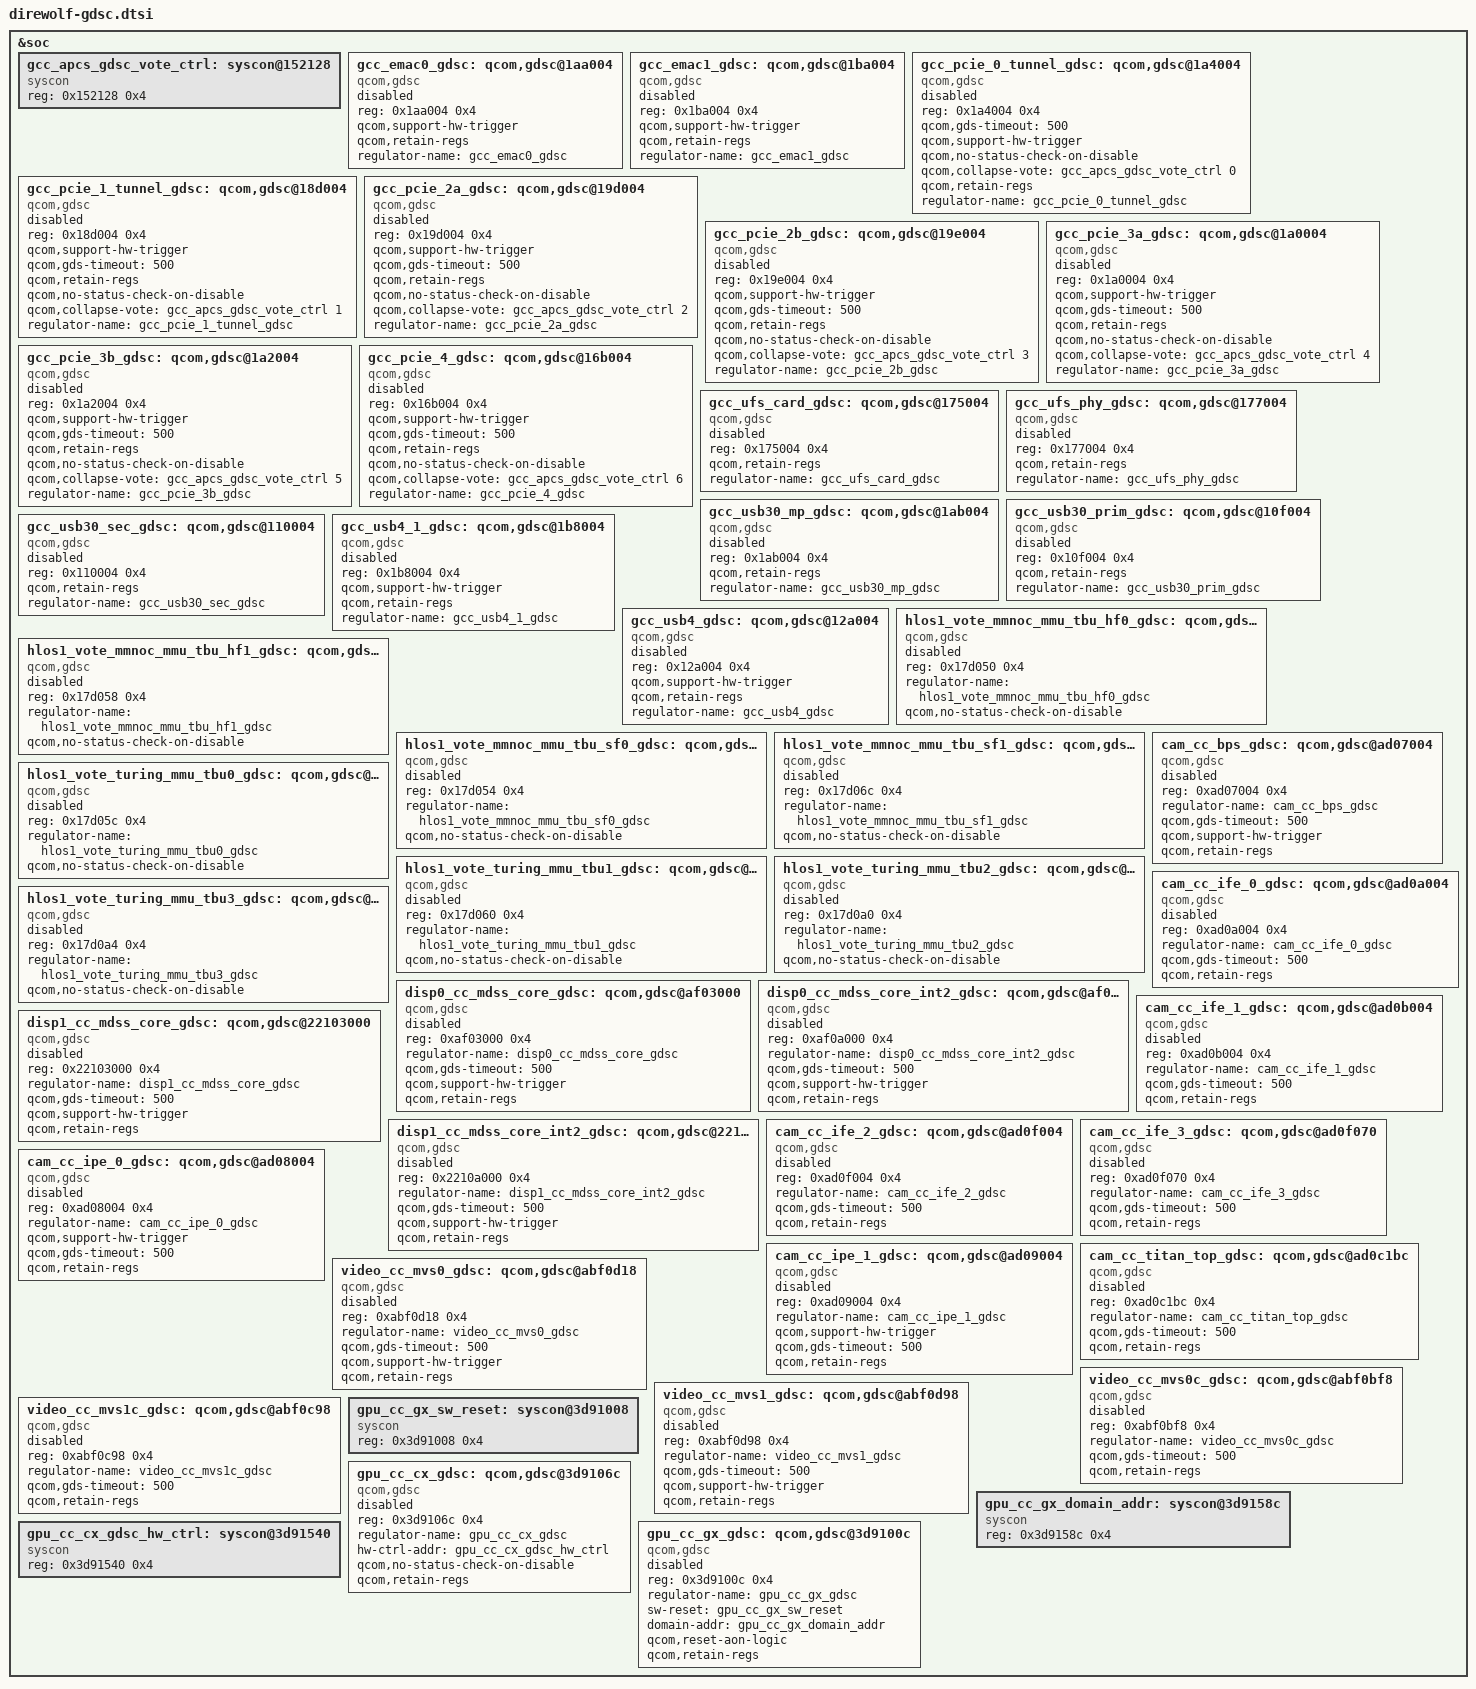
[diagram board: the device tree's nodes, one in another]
&soc {
	gcc_apcs_gdsc_vote_ctrl: syscon@152128 {
		compatible = "syscon";
		reg = <0x152128 0x4>;
	};

	/* GDSCs in GCC */
	gcc_emac0_gdsc: qcom,gdsc@1aa004 {
		compatible = "qcom,gdsc";
		reg = <0x1aa004 0x4>;
		qcom,support-hw-trigger;
		qcom,retain-regs;
		regulator-name = "gcc_emac0_gdsc";
		status = "disabled";
	};

	gcc_emac1_gdsc: qcom,gdsc@1ba004 {
		compatible = "qcom,gdsc";
		reg = <0x1ba004 0x4>;
		qcom,support-hw-trigger;
		qcom,retain-regs;
		regulator-name = "gcc_emac1_gdsc";
		status = "disabled";
	};

	gcc_pcie_0_tunnel_gdsc: qcom,gdsc@1a4004 {
		compatible = "qcom,gdsc";
		reg = <0x1a4004 0x4>;
		qcom,gds-timeout = <500>;
		qcom,support-hw-trigger;
		qcom,no-status-check-on-disable;
		qcom,collapse-vote = <&gcc_apcs_gdsc_vote_ctrl 0>;
		qcom,retain-regs;
		regulator-name = "gcc_pcie_0_tunnel_gdsc";
		status = "disabled";
	};

	gcc_pcie_1_tunnel_gdsc: qcom,gdsc@18d004 {
		compatible = "qcom,gdsc";
		reg = <0x18d004 0x4>;
		qcom,support-hw-trigger;
		qcom,gds-timeout = <500>;
		qcom,retain-regs;
		qcom,no-status-check-on-disable;
		qcom,collapse-vote = <&gcc_apcs_gdsc_vote_ctrl 1>;
		regulator-name = "gcc_pcie_1_tunnel_gdsc";
		status = "disabled";
	};

	gcc_pcie_2a_gdsc: qcom,gdsc@19d004 {
		compatible = "qcom,gdsc";
		reg = <0x19d004 0x4>;
		qcom,support-hw-trigger;
		qcom,gds-timeout = <500>;
		qcom,retain-regs;
		qcom,no-status-check-on-disable;
		qcom,collapse-vote = <&gcc_apcs_gdsc_vote_ctrl 2>;
		regulator-name = "gcc_pcie_2a_gdsc";
		status = "disabled";
	};

	gcc_pcie_2b_gdsc: qcom,gdsc@19e004 {
		compatible = "qcom,gdsc";
		reg = <0x19e004 0x4>;
		qcom,support-hw-trigger;
		qcom,gds-timeout = <500>;
		qcom,retain-regs;
		qcom,no-status-check-on-disable;
		qcom,collapse-vote = <&gcc_apcs_gdsc_vote_ctrl 3>;
		regulator-name = "gcc_pcie_2b_gdsc";
		status = "disabled";
	};

	gcc_pcie_3a_gdsc: qcom,gdsc@1a0004 {
		compatible = "qcom,gdsc";
		reg = <0x1a0004 0x4>;
		qcom,support-hw-trigger;
		qcom,gds-timeout = <500>;
		qcom,retain-regs;
		qcom,no-status-check-on-disable;
		qcom,collapse-vote = <&gcc_apcs_gdsc_vote_ctrl 4>;
		regulator-name = "gcc_pcie_3a_gdsc";
		status = "disabled";
	};

	gcc_pcie_3b_gdsc: qcom,gdsc@1a2004 {
		compatible = "qcom,gdsc";
		reg = <0x1a2004 0x4>;
		qcom,support-hw-trigger;
		qcom,gds-timeout = <500>;
		qcom,retain-regs;
		qcom,no-status-check-on-disable;
		qcom,collapse-vote = <&gcc_apcs_gdsc_vote_ctrl 5>;
		regulator-name = "gcc_pcie_3b_gdsc";
		status = "disabled";
	};

	gcc_pcie_4_gdsc: qcom,gdsc@16b004 {
		compatible = "qcom,gdsc";
		reg = <0x16b004 0x4>;
		qcom,support-hw-trigger;
		qcom,gds-timeout = <500>;
		qcom,retain-regs;
		qcom,no-status-check-on-disable;
		qcom,collapse-vote = <&gcc_apcs_gdsc_vote_ctrl 6>;
		regulator-name = "gcc_pcie_4_gdsc";
		status = "disabled";
	};

	gcc_ufs_card_gdsc: qcom,gdsc@175004 {
		compatible = "qcom,gdsc";
		reg = <0x175004 0x4>;
		qcom,retain-regs;
		regulator-name = "gcc_ufs_card_gdsc";
		status = "disabled";
	};

	gcc_ufs_phy_gdsc: qcom,gdsc@177004 {
		compatible = "qcom,gdsc";
		reg = <0x177004 0x4>;
		qcom,retain-regs;
		regulator-name = "gcc_ufs_phy_gdsc";
		status = "disabled";
	};

	gcc_usb30_mp_gdsc: qcom,gdsc@1ab004 {
		compatible = "qcom,gdsc";
		reg = <0x1ab004 0x4>;
		qcom,retain-regs;
		regulator-name = "gcc_usb30_mp_gdsc";
		status = "disabled";
	};

	gcc_usb30_prim_gdsc: qcom,gdsc@10f004 {
		compatible = "qcom,gdsc";
		reg = <0x10f004 0x4>;
		qcom,retain-regs;
		regulator-name = "gcc_usb30_prim_gdsc";
		status = "disabled";
	};

	gcc_usb30_sec_gdsc: qcom,gdsc@110004 {
		compatible = "qcom,gdsc";
		reg = <0x110004 0x4>;
		qcom,retain-regs;
		regulator-name = "gcc_usb30_sec_gdsc";
		status = "disabled";
	};

	gcc_usb4_1_gdsc: qcom,gdsc@1b8004 {
		compatible = "qcom,gdsc";
		reg = <0x1b8004 0x4>;
		qcom,support-hw-trigger;
		qcom,retain-regs;
		regulator-name = "gcc_usb4_1_gdsc";
		status = "disabled";
	};

	gcc_usb4_gdsc: qcom,gdsc@12a004 {
		compatible = "qcom,gdsc";
		reg = <0x12a004 0x4>;
		qcom,support-hw-trigger;
		qcom,retain-regs;
		regulator-name = "gcc_usb4_gdsc";
		status = "disabled";
	};

	hlos1_vote_mmnoc_mmu_tbu_hf0_gdsc: qcom,gdsc@17d050 {
		compatible = "qcom,gdsc";
		reg = <0x17d050 0x4>;
		regulator-name = "hlos1_vote_mmnoc_mmu_tbu_hf0_gdsc";
		qcom,no-status-check-on-disable;
		status = "disabled";
	};

	hlos1_vote_mmnoc_mmu_tbu_hf1_gdsc: qcom,gdsc@17d058 {
		compatible = "qcom,gdsc";
		reg = <0x17d058 0x4>;
		regulator-name = "hlos1_vote_mmnoc_mmu_tbu_hf1_gdsc";
		qcom,no-status-check-on-disable;
		status = "disabled";
	};

	hlos1_vote_mmnoc_mmu_tbu_sf0_gdsc: qcom,gdsc@17d054 {
		compatible = "qcom,gdsc";
		reg = <0x17d054 0x4>;
		regulator-name = "hlos1_vote_mmnoc_mmu_tbu_sf0_gdsc";
		qcom,no-status-check-on-disable;
		status = "disabled";
	};

	hlos1_vote_mmnoc_mmu_tbu_sf1_gdsc: qcom,gdsc@17d06c {
		compatible = "qcom,gdsc";
		reg = <0x17d06c 0x4>;
		regulator-name = "hlos1_vote_mmnoc_mmu_tbu_sf1_gdsc";
		qcom,no-status-check-on-disable;
		status = "disabled";
	};

	hlos1_vote_turing_mmu_tbu0_gdsc: qcom,gdsc@17d05c {
		compatible = "qcom,gdsc";
		reg = <0x17d05c 0x4>;
		regulator-name = "hlos1_vote_turing_mmu_tbu0_gdsc";
		qcom,no-status-check-on-disable;
		status = "disabled";
	};

	hlos1_vote_turing_mmu_tbu1_gdsc: qcom,gdsc@17d060 {
		compatible = "qcom,gdsc";
		reg = <0x17d060 0x4>;
		regulator-name = "hlos1_vote_turing_mmu_tbu1_gdsc";
		qcom,no-status-check-on-disable;
		status = "disabled";
	};

	hlos1_vote_turing_mmu_tbu2_gdsc: qcom,gdsc@17d0a0 {
		compatible = "qcom,gdsc";
		reg = <0x17d0a0 0x4>;
		regulator-name = "hlos1_vote_turing_mmu_tbu2_gdsc";
		qcom,no-status-check-on-disable;
		status = "disabled";
	};

	hlos1_vote_turing_mmu_tbu3_gdsc: qcom,gdsc@17d0a4 {
		compatible = "qcom,gdsc";
		reg = <0x17d0a4 0x4>;
		regulator-name = "hlos1_vote_turing_mmu_tbu3_gdsc";
		qcom,no-status-check-on-disable;
		status = "disabled";
	};

	/* DISP_CC_0 GDSCs */
	disp0_cc_mdss_core_gdsc: qcom,gdsc@af03000 {
		compatible = "qcom,gdsc";
		reg = <0xaf03000 0x4>;
		regulator-name = "disp0_cc_mdss_core_gdsc";
		qcom,gds-timeout = <500>;
		qcom,support-hw-trigger;
		qcom,retain-regs;
		status = "disabled";
	};

	disp0_cc_mdss_core_int2_gdsc: qcom,gdsc@af0a000 {
		compatible = "qcom,gdsc";
		reg = <0xaf0a000 0x4>;
		regulator-name = "disp0_cc_mdss_core_int2_gdsc";
		qcom,gds-timeout = <500>;
		qcom,support-hw-trigger;
		qcom,retain-regs;
		status = "disabled";
	};

	/* DISP_CC_1 GDSCs */
	disp1_cc_mdss_core_gdsc: qcom,gdsc@22103000 {
		compatible = "qcom,gdsc";
		reg = <0x22103000 0x4>;
		regulator-name = "disp1_cc_mdss_core_gdsc";
		qcom,gds-timeout = <500>;
		qcom,support-hw-trigger;
		qcom,retain-regs;
		status = "disabled";
	};

	disp1_cc_mdss_core_int2_gdsc: qcom,gdsc@2210a000 {
		compatible = "qcom,gdsc";
		reg = <0x2210a000 0x4>;
		regulator-name = "disp1_cc_mdss_core_int2_gdsc";
		qcom,gds-timeout = <500>;
		qcom,support-hw-trigger;
		qcom,retain-regs;
		status = "disabled";
	};

	/* CAM_CC GDSCs */
	cam_cc_bps_gdsc: qcom,gdsc@ad07004 {
		compatible = "qcom,gdsc";
		reg = <0xad07004 0x4>;
		regulator-name = "cam_cc_bps_gdsc";
		qcom,gds-timeout = <500>;
		qcom,support-hw-trigger;
		qcom,retain-regs;
		status = "disabled";
	};

	cam_cc_ife_0_gdsc: qcom,gdsc@ad0a004 {
		compatible = "qcom,gdsc";
		reg = <0xad0a004 0x4>;
		regulator-name = "cam_cc_ife_0_gdsc";
		qcom,gds-timeout = <500>;
		qcom,retain-regs;
		status = "disabled";
	};

	cam_cc_ife_1_gdsc: qcom,gdsc@ad0b004 {
		compatible = "qcom,gdsc";
		reg = <0xad0b004 0x4>;
		regulator-name = "cam_cc_ife_1_gdsc";
		qcom,gds-timeout = <500>;
		qcom,retain-regs;
		status = "disabled";
	};

	cam_cc_ife_2_gdsc: qcom,gdsc@ad0f004 {
		compatible = "qcom,gdsc";
		reg = <0xad0f004 0x4>;
		regulator-name = "cam_cc_ife_2_gdsc";
		qcom,gds-timeout = <500>;
		qcom,retain-regs;
		status = "disabled";
	};

	cam_cc_ife_3_gdsc: qcom,gdsc@ad0f070 {
		compatible = "qcom,gdsc";
		reg = <0xad0f070 0x4>;
		regulator-name = "cam_cc_ife_3_gdsc";
		qcom,gds-timeout = <500>;
		qcom,retain-regs;
		status = "disabled";
	};

	cam_cc_ipe_0_gdsc: qcom,gdsc@ad08004 {
		compatible = "qcom,gdsc";
		reg = <0xad08004 0x4>;
		regulator-name = "cam_cc_ipe_0_gdsc";
		qcom,support-hw-trigger;
		qcom,gds-timeout = <500>;
		qcom,retain-regs;
		status = "disabled";
	};

	cam_cc_ipe_1_gdsc: qcom,gdsc@ad09004 {
		compatible = "qcom,gdsc";
		reg = <0xad09004 0x4>;
		regulator-name = "cam_cc_ipe_1_gdsc";
		qcom,support-hw-trigger;
		qcom,gds-timeout = <500>;
		qcom,retain-regs;
		status = "disabled";
	};

	cam_cc_titan_top_gdsc: qcom,gdsc@ad0c1bc {
		compatible = "qcom,gdsc";
		reg = <0xad0c1bc 0x4>;
		regulator-name = "cam_cc_titan_top_gdsc";
		qcom,gds-timeout = <500>;
		qcom,retain-regs;
		status = "disabled";
	};

	/* VIDEO_CC GDSCs */
	video_cc_mvs0_gdsc: qcom,gdsc@abf0d18 {
		compatible = "qcom,gdsc";
		reg = <0xabf0d18 0x4>;
		regulator-name = "video_cc_mvs0_gdsc";
		qcom,gds-timeout = <500>;
		qcom,support-hw-trigger;
		qcom,retain-regs;
		status = "disabled";
	};

	video_cc_mvs0c_gdsc: qcom,gdsc@abf0bf8 {
		compatible = "qcom,gdsc";
		reg = <0xabf0bf8 0x4>;
		regulator-name = "video_cc_mvs0c_gdsc";
		qcom,gds-timeout = <500>;
		qcom,retain-regs;
		status = "disabled";
	};

	video_cc_mvs1_gdsc: qcom,gdsc@abf0d98 {
		compatible = "qcom,gdsc";
		reg = <0xabf0d98 0x4>;
		regulator-name = "video_cc_mvs1_gdsc";
		qcom,gds-timeout = <500>;
		qcom,support-hw-trigger;
		qcom,retain-regs;
		status = "disabled";
	};

	video_cc_mvs1c_gdsc: qcom,gdsc@abf0c98 {
		compatible = "qcom,gdsc";
		reg = <0xabf0c98 0x4>;
		regulator-name = "video_cc_mvs1c_gdsc";
		qcom,gds-timeout = <500>;
		qcom,retain-regs;
		status = "disabled";
	};

	/* GPU_CC GDSCs */
	gpu_cc_gx_domain_addr: syscon@3d9158c {
		compatible = "syscon";
		reg = <0x3d9158c 0x4>;
	};

	gpu_cc_cx_gdsc_hw_ctrl: syscon@3d91540 {
		compatible = "syscon";
		reg = <0x3d91540 0x4>;
	};

	gpu_cc_gx_sw_reset: syscon@3d91008 {
		compatible = "syscon";
		reg = <0x3d91008 0x4>;
	};

	gpu_cc_cx_gdsc: qcom,gdsc@3d9106c {
		compatible = "qcom,gdsc";
		reg = <0x3d9106c 0x4>;
		regulator-name = "gpu_cc_cx_gdsc";
		hw-ctrl-addr = <&gpu_cc_cx_gdsc_hw_ctrl>;
		qcom,no-status-check-on-disable;
		qcom,retain-regs;
		status = "disabled";
	};

	gpu_cc_gx_gdsc: qcom,gdsc@3d9100c {
		compatible = "qcom,gdsc";
		reg = <0x3d9100c 0x4>;
		regulator-name = "gpu_cc_gx_gdsc";
		sw-reset = <&gpu_cc_gx_sw_reset>;
		domain-addr = <&gpu_cc_gx_domain_addr>;
		qcom,reset-aon-logic;
		qcom,retain-regs;
		status = "disabled";
	};

};
